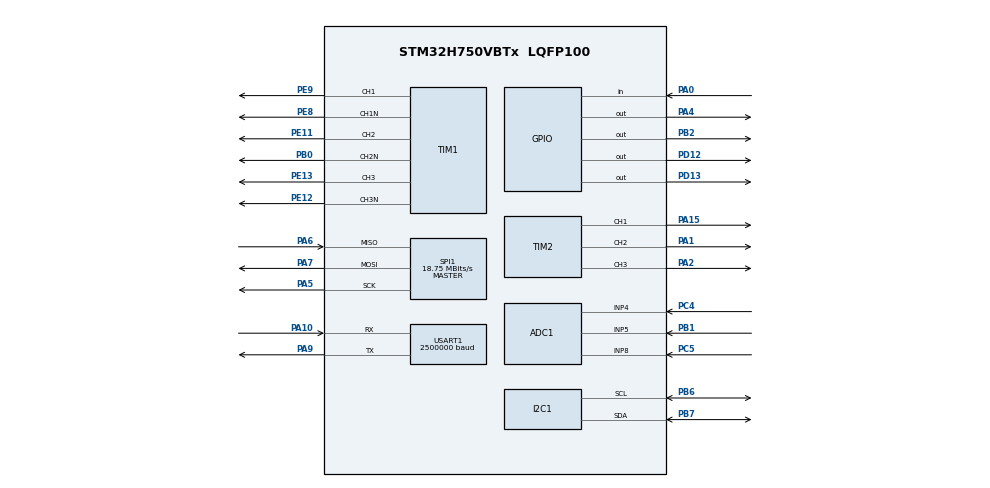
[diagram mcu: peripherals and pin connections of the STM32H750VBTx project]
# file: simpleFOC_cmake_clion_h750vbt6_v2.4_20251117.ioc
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ADC1.Channel-0\#ChannelRegularConversion=ADC_CHANNEL_4
ADC1.ClockPrescaler=ADC_CLOCK_ASYNC_DIV2
ADC1.EnableInjectedConversion=ENABLE
ADC1.ExternalTrigInjecConv=ADC_EXTERNALTRIGINJEC_T1_CC4
ADC1.ExternalTrigInjecConvEdge=ADC_EXTERNALTRIGINJECCONV_EDGE_FALLING
ADC1.InjNumberOfConversion=3
ADC1.InjectedChannel-1\#ChannelInjectedConversion=ADC_CHANNEL_5
ADC1.InjectedChannel-2\#ChannelInjectedConversion=ADC_CHANNEL_4
ADC1.InjectedChannel-3\#ChannelInjectedConversion=ADC_CHANNEL_8
ADC1.InjectedOffsetNumber-1\#ChannelInjectedConversion=ADC_OFFSET_NONE
ADC1.InjectedOffsetNumber-2\#ChannelInjectedConversion=ADC_OFFSET_NONE
ADC1.InjectedOffsetNumber-3\#ChannelInjectedConversion=ADC_OFFSET_NONE
ADC1.InjectedOffsetSaturation-1\#ChannelInjectedConversion=DISABLE
ADC1.InjectedOffsetSaturation-2\#ChannelInjectedConversion=DISABLE
ADC1.InjectedOffsetSaturation-3\#ChannelInjectedConversion=DISABLE
ADC1.InjectedOffsetSignedSaturation-1\#ChannelInjectedConversion=DISABLE
ADC1.InjectedOffsetSignedSaturation-2\#ChannelInjectedConversion=DISABLE
ADC1.InjectedOffsetSignedSaturation-3\#ChannelInjectedConversion=DISABLE
ADC1.InjectedRank-1\#ChannelInjectedConversion=1
ADC1.InjectedRank-2\#ChannelInjectedConversion=2
ADC1.InjectedRank-3\#ChannelInjectedConversion=3
ADC1.InjectedSamplingTime-1\#ChannelInjectedConversion=ADC_SAMPLETIME_1CYCLE_5
ADC1.InjectedSamplingTime-2\#ChannelInjectedConversion=ADC_SAMPLETIME_1CYCLE_5
ADC1.InjectedSamplingTime-3\#ChannelInjectedConversion=ADC_SAMPLETIME_1CYCLE_5
ADC1.NbrOfConversionFlag=1
ADC1.OffsetNumber-0\#ChannelRegularConversion=ADC_OFFSET_NONE
ADC1.OffsetSignedSaturation-0\#ChannelRegularConversion=DISABLE
ADC1.Rank-0\#ChannelRegularConversion=1
ADC1.SamplingTime-0\#ChannelRegularConversion=ADC_SAMPLETIME_1CYCLE_5
ADC1.master=1
CORTEX_M7.default_mode_Activation=1
Dma.Request0=USART1_TX
Dma.USART1_TX.0.Direction=DMA_MEMORY_TO_PERIPH
Dma.USART1_TX.0.EventEnable=DISABLE
Dma.USART1_TX.0.FIFOMode=DMA_FIFOMODE_DISABLE
Dma.USART1_TX.0.Instance=DMA1_Stream0
Dma.USART1_TX.0.MemDataAlignment=DMA_MDATAALIGN_BYTE
Dma.USART1_TX.0.MemInc=DMA_MINC_ENABLE
Dma.USART1_TX.0.Mode=DMA_NORMAL
Dma.USART1_TX.0.PeriphDataAlignment=DMA_PDATAALIGN_BYTE
Dma.USART1_TX.0.PeriphInc=DMA_PINC_DISABLE
Dma.USART1_TX.0.Polarity=HAL_DMAMUX_REQ_GEN_RISING
Dma.USART1_TX.0.Priority=DMA_PRIORITY_LOW
Dma.USART1_TX.0.RequestNumber=1
Dma.USART1_TX.0.SignalID=NONE
Dma.USART1_TX.0.SyncEnable=DISABLE
Dma.USART1_TX.0.SyncPolarity=HAL_DMAMUX_SYNC_NO_EVENT
Dma.USART1_TX.0.SyncRequestNumber=1
Dma.USART1_TX.0.SyncSignalID=NONE
I2C1.Timing=0x307075B1
Mcu.Family=STM32H7
Mcu.Name=STM32H750VBTx
Mcu.Package=LQFP100
NVIC.ADC_IRQn=true\:0\:0\:false\:false\:true\:true\:true\:true
NVIC.DMA1_Stream0_IRQn=true\:0\:0\:false\:false\:true\:false\:true\:true
NVIC.PriorityGroup=NVIC_PRIORITYGROUP_4
NVIC.TIM1_BRK_IRQn=true\:0\:0\:false\:false\:true\:true\:true\:true
NVIC.TIM1_CC_IRQn=true\:0\:0\:false\:false\:true\:true\:true\:true
NVIC.TIM1_TRG_COM_IRQn=true\:0\:0\:false\:false\:true\:true\:true\:true
NVIC.TIM1_UP_IRQn=true\:0\:0\:false\:false\:true\:true\:true\:true
NVIC.TIM2_IRQn=true\:0\:0\:false\:false\:true\:true\:true\:true
NVIC.USART1_IRQn=true\:0\:0\:false\:false\:true\:true\:true\:true
PA0.GPIO_PuPd=GPIO_PULLDOWN
PA0.Signal=GPIO_Input
PA1.Signal=S_TIM2_CH2
PA10.Mode=Asynchronous
PA10.Signal=USART1_RX
PA15\ (JTDI).Signal=S_TIM2_CH1_ETR
PA2.Signal=S_TIM2_CH3
PA4.Signal=GPIO_Output
PA5.Mode=Full_Duplex_Master
PA5.Signal=SPI1_SCK
PA6.Mode=Full_Duplex_Master
PA6.Signal=SPI1_MISO
PA7.Mode=Full_Duplex_Master
PA7.Signal=SPI1_MOSI
PA9.Mode=Asynchronous
PA9.Signal=USART1_TX
PB0.Mode=PWM Generation2 CH2 CH2N
PB0.Signal=TIM1_CH2N
PB1.Signal=ADCx_INP5
PB2.Signal=GPIO_Output
PB6.Mode=I2C
PB6.Signal=I2C1_SCL
PB7.Mode=I2C
PB7.Signal=I2C1_SDA
PC4.Signal=ADCx_INP4
PC5.Signal=ADCx_INP8
PD12.Signal=GPIO_Output
PD13.Signal=GPIO_Output
PE11.Signal=S_TIM1_CH2
PE12.Mode=PWM Generation3 CH3 CH3N
PE12.Signal=TIM1_CH3N
PE13.Signal=S_TIM1_CH3
PE8.Mode=PWM Generation1 CH1 CH1N
PE8.Signal=TIM1_CH1N
PE9.Signal=S_TIM1_CH1
PH0-OSC_IN\ (PH0).Mode=HSE-External-Oscillator
PH0-OSC_IN\ (PH0).Signal=RCC_OSC_IN
PH1-OSC_OUT\ (PH1).Mode=HSE-External-Oscillator
PH1-OSC_OUT\ (PH1).Signal=RCC_OSC_OUT
ProjectManager.HeapSize=0x200
ProjectManager.StackSize=0x400
ProjectManager.TargetToolchain=CMake
RCC.ADCFreq_Value=75000000
RCC.APB1Freq_Value=120000000
RCC.APB2Freq_Value=120000000
RCC.APB3Freq_Value=120000000
RCC.APB4Freq_Value=120000000
RCC.CortexFreq_Value=480000000
RCC.D1PPRE=RCC_APB3_DIV2
RCC.D2PPRE1=RCC_APB1_DIV2
RCC.D2PPRE2=RCC_APB2_DIV2
RCC.D3PPRE=RCC_APB4_DIV2
RCC.DIVM1=5
RCC.DIVM2=2
RCC.DIVN1=192
RCC.DIVN2=12
RCC.HCLKFreq_Value=240000000
RCC.HPRE=RCC_HCLK_DIV2
RCC.PLL2FRACN=0
RCC.PLL3FRACN=0
RCC.PLLFRACN=0
RCC.PLLSourceVirtual=RCC_PLLSOURCE_HSE
RCC.SPI123CLockSelection=RCC_SPI123CLKSOURCE_PLL2
RCC.SYSCLKFreq_VALUE=480000000
RCC.SYSCLKSource=RCC_SYSCLKSOURCE_PLLCLK
RCC.USBFreq_Value=480000000
SH.ADCx_INP4.0=ADC1_INP4,IN4-Single-Ended
SH.ADCx_INP5.0=ADC1_INP5,IN5-Single-Ended
SH.ADCx_INP8.0=ADC1_INP8,IN8-Single-Ended
SH.S_TIM1_CH1.0=TIM1_CH1,PWM Generation1 CH1 CH1N
SH.S_TIM1_CH2.0=TIM1_CH2,PWM Generation2 CH2 CH2N
SH.S_TIM1_CH3.0=TIM1_CH3,PWM Generation3 CH3 CH3N
SH.S_TIM2_CH1_ETR.0=TIM2_CH1,PWM Generation1 CH1
SH.S_TIM2_CH2.0=TIM2_CH2,PWM Generation2 CH2
SH.S_TIM2_CH3.0=TIM2_CH3,PWM Generation3 CH3
SPI1.BaudRatePrescaler=SPI_BAUDRATEPRESCALER_4
SPI1.CalculateBaudRate=18.75 MBits/s
SPI1.DataSize=SPI_DATASIZE_8BIT
SPI1.Direction=SPI_DIRECTION_2LINES
SPI1.Mode=SPI_MODE_MASTER
SPI1.VirtualType=VM_MASTER
TIM1.AutoReloadPreload=TIM_AUTORELOAD_PRELOAD_ENABLE
TIM1.Channel-PWM\ Generation1\ CH1\ CH1N=TIM_CHANNEL_1
TIM1.Channel-PWM\ Generation2\ CH2\ CH2N=TIM_CHANNEL_2
TIM1.Channel-PWM\ Generation3\ CH3\ CH3N=TIM_CHANNEL_3
TIM1.Channel-PWM\ Generation4\ No\ Output=TIM_CHANNEL_4
TIM1.CounterMode=TIM_COUNTERMODE_CENTERALIGNED1
TIM1.DeadTime=100
TIM1.OCMode_PWM-PWM\ Generation1\ CH1\ CH1N=TIM_OCMODE_PWM2
TIM1.OCMode_PWM-PWM\ Generation2\ CH2\ CH2N=TIM_OCMODE_PWM2
TIM1.OCMode_PWM-PWM\ Generation3\ CH3\ CH3N=TIM_OCMODE_PWM2
TIM1.TIM_MasterOutputTrigger=TIM_TRGO_OC4REF
TIM2.AutoReloadPreload=TIM_AUTORELOAD_PRELOAD_ENABLE
TIM2.Channel-PWM\ Generation1\ CH1=TIM_CHANNEL_1
TIM2.Channel-PWM\ Generation2\ CH2=TIM_CHANNEL_2
TIM2.Channel-PWM\ Generation3\ CH3=TIM_CHANNEL_3
USART1.BaudRate=2500000
USART1.VirtualMode-Asynchronous=VM_ASYNC
VP_MEMORYMAP_VS_MEMORYMAP.Mode=CurAppReg
VP_TIM1_VS_ClockSourceINT.Mode=Internal
VP_TIM1_VS_no_output4.Mode=PWM Generation4 No Output
VP_TIM2_VS_ClockSourceINT.Mode=Internal
board=custom

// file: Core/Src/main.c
/* USER CODE BEGIN Header */
/**
  ******************************************************************************
  * @file           : main.c
  * @brief          : Main program body
  ******************************************************************************
  * @attention
  *
  * Copyright (c) 2025 STMicroelectronics.
  * All rights reserved.
  *
  * This software is licensed under terms that can be found in the LICENSE file
  * in the root directory of this software component.
  * If no LICENSE file comes with this software, it is provided AS-IS.
  *
  ******************************************************************************
  */
/* USER CODE END Header */
#include "main.h"
#include "adc.h"
#include "dma.h"
#include "i2c.h"
#include "spi.h"
#include "tim.h"
#include "usart.h"
#include "gpio.h"

void SystemClock_Config(void);
void PeriphCommonClock_Config(void);
static void MPU_Config(void);

/* USER CODE BEGIN 0 */
extern void test_main(void);

/* USER CODE END 0 */

int main(void)
{

  /* MPU Configuration--------------------------------------------------------*/
  MPU_Config();

  /* MCU Configuration--------------------------------------------------------*/

  /* Reset of all peripherals, Initializes the Flash interface and the Systick. */
  HAL_Init();

  /* Configure the system clock */
  SystemClock_Config();

  /* Configure the peripherals common clocks */
  PeriphCommonClock_Config();

  /* Initialize all configured peripherals */
  MX_GPIO_Init();
  MX_DMA_Init();
  MX_USART1_UART_Init();
  MX_ADC1_Init();
  MX_TIM1_Init();
  MX_I2C1_Init();
  MX_SPI1_Init();
  MX_TIM2_Init();
  /* USER CODE BEGIN 2 */
  test_main();

  /* USER CODE END 2 */

  /* Infinite loop */
  while (1)
  {

    /* USER CODE BEGIN 3 */
    HAL_GPIO_TogglePin(GPIOB, GPIO_PIN_2);
    HAL_Delay(1000);
  }
  /* USER CODE END 3 */
}

void SystemClock_Config(void)
{
  RCC_OscInitTypeDef RCC_OscInitStruct = {0};
  RCC_ClkInitTypeDef RCC_ClkInitStruct = {0};

  /** Supply configuration update enable
  */
  HAL_PWREx_ConfigSupply(PWR_LDO_SUPPLY);

  /** Configure the main internal regulator output voltage
  */
  __HAL_PWR_VOLTAGESCALING_CONFIG(PWR_REGULATOR_VOLTAGE_SCALE0);

  while(!__HAL_PWR_GET_FLAG(PWR_FLAG_VOSRDY)) {}

  /** Initializes the RCC Oscillators according to the specified parameters
  * in the RCC_OscInitTypeDef structure.
  */
  RCC_OscInitStruct.OscillatorType = RCC_OSCILLATORTYPE_HSE;
  RCC_OscInitStruct.HSEState = RCC_HSE_ON;
  RCC_OscInitStruct.PLL.PLLState = RCC_PLL_ON;
  RCC_OscInitStruct.PLL.PLLSource = RCC_PLLSOURCE_HSE;
  RCC_OscInitStruct.PLL.PLLM = 5;
  RCC_OscInitStruct.PLL.PLLN = 192;
  RCC_OscInitStruct.PLL.PLLP = 2;
  RCC_OscInitStruct.PLL.PLLQ = 2;
  RCC_OscInitStruct.PLL.PLLR = 2;
  RCC_OscInitStruct.PLL.PLLRGE = RCC_PLL1VCIRANGE_2;
  RCC_OscInitStruct.PLL.PLLVCOSEL = RCC_PLL1VCOWIDE;
  RCC_OscInitStruct.PLL.PLLFRACN = 0;
  if (HAL_RCC_OscConfig(&RCC_OscInitStruct) != HAL_OK)
  {
    Error_Handler();
  }

  /** Initializes the CPU, AHB and APB buses clocks
  */
  RCC_ClkInitStruct.ClockType = RCC_CLOCKTYPE_HCLK|RCC_CLOCKTYPE_SYSCLK
                              |RCC_CLOCKTYPE_PCLK1|RCC_CLOCKTYPE_PCLK2
                              |RCC_CLOCKTYPE_D3PCLK1|RCC_CLOCKTYPE_D1PCLK1;
  RCC_ClkInitStruct.SYSCLKSource = RCC_SYSCLKSOURCE_PLLCLK;
  RCC_ClkInitStruct.SYSCLKDivider = RCC_SYSCLK_DIV1;
  RCC_ClkInitStruct.AHBCLKDivider = RCC_HCLK_DIV2;
  RCC_ClkInitStruct.APB3CLKDivider = RCC_APB3_DIV2;
  RCC_ClkInitStruct.APB1CLKDivider = RCC_APB1_DIV2;
  RCC_ClkInitStruct.APB2CLKDivider = RCC_APB2_DIV2;
  RCC_ClkInitStruct.APB4CLKDivider = RCC_APB4_DIV2;

  if (HAL_RCC_ClockConfig(&RCC_ClkInitStruct, FLASH_LATENCY_4) != HAL_OK)
  {
    Error_Handler();
  }
}

void PeriphCommonClock_Config(void)
{
  RCC_PeriphCLKInitTypeDef PeriphClkInitStruct = {0};

  /** Initializes the peripherals clock
  */
  PeriphClkInitStruct.PeriphClockSelection = RCC_PERIPHCLK_ADC|RCC_PERIPHCLK_SPI1;
  PeriphClkInitStruct.PLL2.PLL2M = 2;
  PeriphClkInitStruct.PLL2.PLL2N = 12;
  PeriphClkInitStruct.PLL2.PLL2P = 2;
  PeriphClkInitStruct.PLL2.PLL2Q = 2;
  PeriphClkInitStruct.PLL2.PLL2R = 2;
  PeriphClkInitStruct.PLL2.PLL2RGE = RCC_PLL2VCIRANGE_3;
  PeriphClkInitStruct.PLL2.PLL2VCOSEL = RCC_PLL2VCOMEDIUM;
  PeriphClkInitStruct.PLL2.PLL2FRACN = 0;
  PeriphClkInitStruct.Spi123ClockSelection = RCC_SPI123CLKSOURCE_PLL2;
  PeriphClkInitStruct.AdcClockSelection = RCC_ADCCLKSOURCE_PLL2;
  if (HAL_RCCEx_PeriphCLKConfig(&PeriphClkInitStruct) != HAL_OK)
  {
    Error_Handler();
  }
}

 /* MPU Configuration */

void MPU_Config(void)
{
  MPU_Region_InitTypeDef MPU_InitStruct = {0};

  /* Disables the MPU */
  HAL_MPU_Disable();

  /** Initializes and configures the Region and the memory to be protected
  */
  MPU_InitStruct.Enable = MPU_REGION_ENABLE;
  MPU_InitStruct.Number = MPU_REGION_NUMBER0;
  MPU_InitStruct.BaseAddress = 0x0;
  MPU_InitStruct.Size = MPU_REGION_SIZE_4GB;
  MPU_InitStruct.SubRegionDisable = 0x87;
  MPU_InitStruct.TypeExtField = MPU_TEX_LEVEL0;
  MPU_InitStruct.AccessPermission = MPU_REGION_NO_ACCESS;
  MPU_InitStruct.DisableExec = MPU_INSTRUCTION_ACCESS_DISABLE;
  MPU_InitStruct.IsShareable = MPU_ACCESS_SHAREABLE;
  MPU_InitStruct.IsCacheable = MPU_ACCESS_NOT_CACHEABLE;
  MPU_InitStruct.IsBufferable = MPU_ACCESS_NOT_BUFFERABLE;

  HAL_MPU_ConfigRegion(&MPU_InitStruct);
  /* Enables the MPU */
  HAL_MPU_Enable(MPU_PRIVILEGED_DEFAULT);

}

void Error_Handler(void)
{
  __disable_irq();
  while (1)
  {
  }
}
